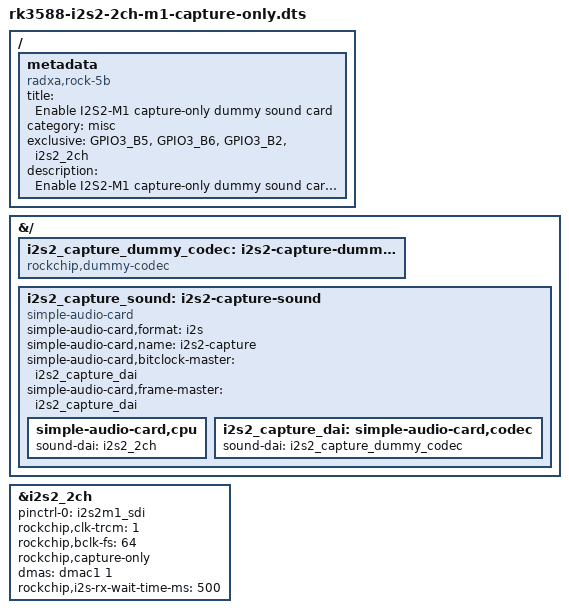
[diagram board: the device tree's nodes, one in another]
/dts-v1/;
/plugin/;

/ {
	metadata {
		title = "Enable I2S2-M1 capture-only dummy sound card";
		compatible = "radxa,rock-5b", "radxa,rock-5b-plus", "radxa,rock-5t", "radxa,rock-5t-industrial";
		category = "misc";
		exclusive = "GPIO3_B5", "GPIO3_B6", "GPIO3_B2", "i2s2_2ch";
		description = "Enable I2S2-M1 capture-only dummy sound card in slave mode.
On Radxa ROCK 5B this is pin38 for SDI0, pin35 for LRCK, pin12 for SCLK.
On Radxa ROCK 5B+ this is pin38 for SDI0, pin35 for LRCK, pin12 for SCLK.
On Radxa ROCK 5T this is pin38 for SDI0, pin35 for LRCK, pin12 for SCLK.
On Radxa ROCK 5T Industrial this is pin38 for SDI0, pin35 for LRCK, pin12 for SCLK.
";
	};
};

&{/} {
	i2s2_capture_dummy_codec: i2s2-capture-dummy-codec {
		compatible = "rockchip,dummy-codec";
		#sound-dai-cells = <0>;
	};

	i2s2_capture_sound: i2s2-capture-sound {
		compatible = "simple-audio-card";
		simple-audio-card,format = "i2s";
		simple-audio-card,name = "i2s2-capture";
		simple-audio-card,bitclock-master = <&i2s2_capture_dai>;
		simple-audio-card,frame-master = <&i2s2_capture_dai>;

		simple-audio-card,cpu {
			sound-dai = <&i2s2_2ch>;
		};

		i2s2_capture_dai: simple-audio-card,codec {
			sound-dai = <&i2s2_capture_dummy_codec>;
		};
	};
};

&i2s2_2ch {
	status = "okay";
	pinctrl-0 = <&i2s2m1_sdi>;
	rockchip,clk-trcm = <1>;
	rockchip,bclk-fs = <64>;
	rockchip,capture-only;
	dmas = <&dmac1 1>;
	dma-names = "rx";
	rockchip,i2s-rx-wait-time-ms = <500>;
};
